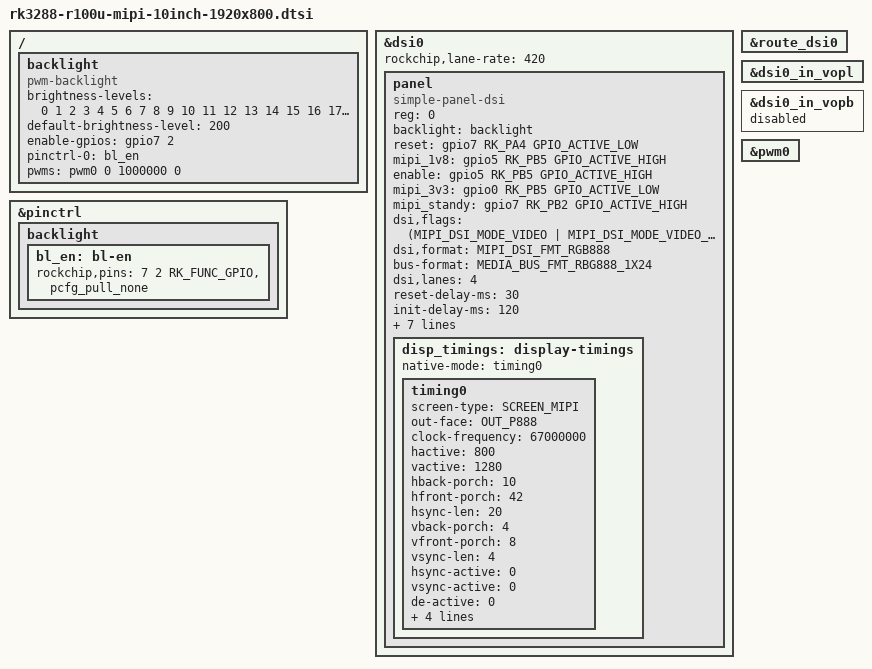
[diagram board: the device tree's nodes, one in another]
#include <dt-bindings/pwm/pwm.h>
#include "rk3288.dtsi"

/ {
    /* about backlight */

    backlight: backlight {
    compatible = "pwm-backlight";
    brightness-levels = 
        <
          0   1   2   3   4   5   6   7
          8   9  10  11  12  13  14  15
         16  17  18  19  20  21  22  23
         24  25  26  27  28  29  30  31
         32  33  34  35  36  37  38  39
         40  41  42  43  44  45  46  47
         48  49  50  51  52  53  54  55
         56  57  58  59  60  61  62  63
         64  65  66  67  68  69  70  71
         72  73  74  75  76  77  78  79
         80  81  82  83  84  85  86  87
         88  89  90  91  92  93  94  95
         96  97  98  99 100 101 102 103
        104 105 106 107 108 109 110 111
        112 113 114 115 116 117 118 119
        120 121 122 123 124 125 126 127
        128 129 130 131 132 133 134 135
        136 137 138 139 140 141 142 143
        144 145 146 147 148 149 150 151
        152 153 154 155 156 157 158 159
        160 161 162 163 164 165 166 167
        168 169 170 171 172 173 174 175
        176 177 178 179 180 181 182 183
        184 185 186 187 188 189 190 191
        192 193 194 195 196 197 198 199
        200 201 202 203 204 205 206 207
        208 209 210 211 212 213 214 215
        216 217 218 219 220 221 222 223
        224 225 226 227 228 229 230 231
        232 233 234 235 236 237 238 239
        240 241 242 243 244 245 246 247
        248 249 250 251 252 253 254 255>;
        default-brightness-level = <200>;
        enable-gpios = <&gpio7 2 GPIO_ACTIVE_HIGH>;
        pinctrl-names = "default";
        pinctrl-0 = <&bl_en>;
        pwms = <&pwm0 0 1000000 0>;
    };
};

/************************************** pin description **********************************
 * LCD_RST:             GPIO7_A4, High ---> reset
 * BACKLIGHT_ENABLE:    GPIO7_A2, High ---> enable
 * LCD_PWM              pwm0
 * LCD_STANDY           GPIO7_B2, High ---> enable
 * LCM_3V3_ENABLE       GPIO0_B5, Low  ---> enable
 * LCM_1V8_ENABLE       GPIO5_B5, High  ---> enable
******************************************************************************************/

&dsi0 {
    status = "okay";
    rockchip,lane-rate = <420>;
    
    panel: panel {
        status = "okay";
        compatible ="simple-panel-dsi"; 
        reg = <0>;                                    
        backlight = <&backlight>;  

        reset = <&gpio7 RK_PA4 GPIO_ACTIVE_LOW>;
 
        mipi_1v8 = <&gpio5  RK_PB5 GPIO_ACTIVE_HIGH>;
        enable = <&gpio5  RK_PB5 GPIO_ACTIVE_HIGH>;

        mipi_3v3 = <&gpio0  RK_PB5 GPIO_ACTIVE_LOW>;
        mipi_standy = <&gpio7 RK_PB2 GPIO_ACTIVE_HIGH>;
        
        dsi,flags = <(MIPI_DSI_MODE_VIDEO | MIPI_DSI_MODE_VIDEO_BURST | MIPI_DSI_MODE_LPM)>;
        dsi,format = <MIPI_DSI_FMT_RGB888>;
        bus-format = <MEDIA_BUS_FMT_RBG888_1X24>;
        dsi,lanes = <4>;
        //dsi,channel = <1>;
        reset-delay-ms = <30>;
        init-delay-ms = <120>;
        enable-delay-ms = <30>;
        prepare-delay-ms = <30>;
        unprepare-delay-ms = <30>; 
        panel-init-sequence = [  
 
            ---------------------- FIXME -------------------------------

            05 78 01 11
            05 32 01 29
        ];
                    
        panel-exit-sequence = [
            05 16 01 28
            05 78 01 10
        ];
   
    disp_timings: display-timings {
        native-mode = <&timing0>;
        timing0: timing0 {
            screen-type = <SCREEN_MIPI>;
            // screen-type = <SCREEN_DUAL_MIPI>;
            // lvds-format = <LVDS_8BIT_2>;
            out-face    = <OUT_P888>;
            clock-frequency = <67000000>;
            hactive = <800>;
            vactive = <1280>;
            
            hback-porch = <10>;
            hfront-porch = <42>;
            hsync-len = <20>;
            
            vback-porch = <4>;
            vfront-porch = <8>;
            vsync-len = <4>;
            
            
            hsync-active = <0>;
            vsync-active = <0>;
            
            de-active = <0>;
            pixelclk-active = <0>;
            swap-rb = <0>;
            swap-rg = <0>;
            swap-gb = <0>;
        };
	};
     };
};

&route_dsi0 {
	status = "okay";
};

// &grf {
//     status = "okay";
// };

// &mipi_phy_tx1rx1 {
//     status = "okay";
// };


&dsi0_in_vopl {
    status = "okay";
};

&dsi0_in_vopb {
    status = "disabled";
};

&pwm0 {
    status = "okay";
};



&pinctrl {

    backlight {
        bl_en: bl-en {
            rockchip,pins = <7 2 RK_FUNC_GPIO &pcfg_pull_none>;
        };
    };

};
